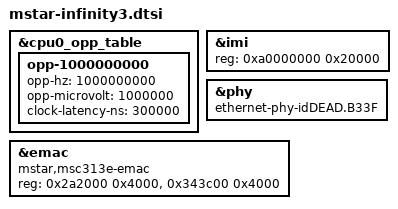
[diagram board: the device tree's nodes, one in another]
// SPDX-License-Identifier: GPL-2.0-or-later
/*
 * Copyright (c) 2020 thingy.jp.
 * Author: Daniel Palmer <daniel@thingy.jp>
 */

#include "mstar-infinity.dtsi"

&cpu0_opp_table {
	opp-1000000000 {
		opp-hz = /bits/ 64 <1000000000>;
		opp-microvolt = <1000000>;
		clock-latency-ns = <300000>;
	};

	/*
	// 100mhz overclock
	opp-1100000000 {
		opp-hz = /bits/ 64 <1100000000>;
		opp-microvolt = <1000000>;
		clock-latency-ns = <300000>;
	};*/
};

&imi {
	reg = <0xa0000000 0x20000>;
};

&phy {
	compatible = "ethernet-phy-idDEAD.B33F";
};

&emac {
	compatible = "mstar,msc313e-emac";
	reg = <0x2a2000 0x4000>,
	      <0x343c00 0x4000>;
};
